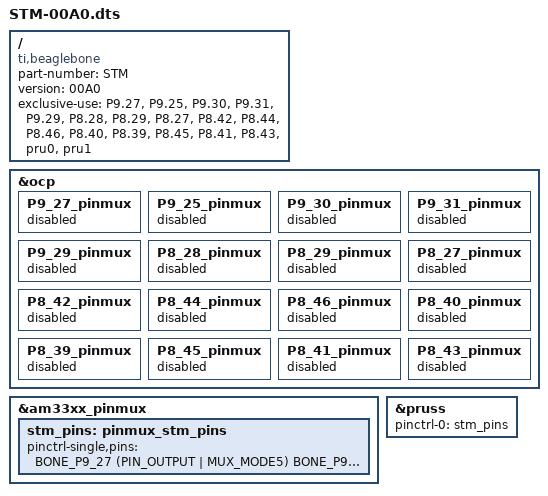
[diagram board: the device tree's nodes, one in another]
// This DTS overlay sets up the GPIO inputs and outputs for the
// scanning-tunneling microscope (STM) firmware

#include <dt-bindings/board/am335x-bbw-bbb-base.h>
#include <dt-bindings/pinctrl/am33xx.h>

/dts-v1/;
/plugin/;

/{
    compatible = "ti,beaglebone", "ti,beaglebone-black";
    part-number = "STM";
    version = "00A0";

    exclusive-use = "P9.27", "P9.25", "P9.30", "P9.31", "P9.29", "P8.28",
    "P8.29", "P8.27", "P8.42", "P8.44", "P8.46", "P8.40", "P8.39", "P8.45",
    "P8.41", "P8.43", "pru0", "pru1";

    /*
    * Free up the pins used by the cape from the pinmux helpers.
    */
    fragment@0 {
        target = <&ocp>;
        __overlay__ {
            P9_27_pinmux { status = "disabled"; };
            P9_25_pinmux { status = "disabled"; };
            P9_30_pinmux { status = "disabled"; };
            P9_31_pinmux { status = "disabled"; };
            P9_29_pinmux { status = "disabled"; };
            P8_28_pinmux { status = "disabled"; };
            P8_29_pinmux { status = "disabled"; };
            P8_27_pinmux { status = "disabled"; };
            P8_42_pinmux { status = "disabled"; };
            P8_44_pinmux { status = "disabled"; };
            P8_46_pinmux { status = "disabled"; };
            P8_40_pinmux { status = "disabled"; };
            P8_39_pinmux { status = "disabled"; };
            P8_45_pinmux { status = "disabled"; };
            P8_41_pinmux { status = "disabled"; };
            P8_43_pinmux { status = "disabled"; };

        };
    };

    fragment@1 {
        target = <&am33xx_pinmux>;
        __overlay__ {
            stm_pins: pinmux_stm_pins {
                pinctrl-single,pins = <
                    BONE_P9_27 (PIN_OUTPUT | MUX_MODE5)
                    BONE_P9_25 (PIN_INPUT  | MUX_MODE6)
                    BONE_P9_30 (PIN_OUTPUT | MUX_MODE5)
                    BONE_P9_31 (PIN_INPUT  | MUX_MODE5)
                    BONE_P9_29 (PIN_INPUT  | MUX_MODE6)
                    BONE_P8_28 (PIN_OUTPUT | MUX_MODE5)
                    BONE_P8_29 (PIN_OUTPUT | MUX_MODE5)
                    BONE_P8_27 (PIN_OUTPUT | MUX_MODE5)
                    BONE_P8_42 (PIN_OUTPUT | MUX_MODE5)
                    BONE_P8_44 (PIN_INPUT  | MUX_MODE6)
                    BONE_P8_46 (PIN_OUTPUT | MUX_MODE5)
                    BONE_P8_40 (PIN_OUTPUT | MUX_MODE5)
                    BONE_P8_39 (PIN_OUTPUT | MUX_MODE5)
                    BONE_P8_45 (PIN_OUTPUT | MUX_MODE5)
                    BONE_P8_41 (PIN_OUTPUT | MUX_MODE5)
                    BONE_P8_43 (PIN_OUTPUT | MUX_MODE5)
                >;
            };
        };
    };

    // This enables the PRU and assigns the GPIO pins to it for use in EGP mode.
    fragment@2 {
        target = <&pruss>;
        __overlay__ {
            status = "okay";
            pinctrl-names = "default";
            pinctrl-0 = <&stm_pins>;
        };
    };
};
